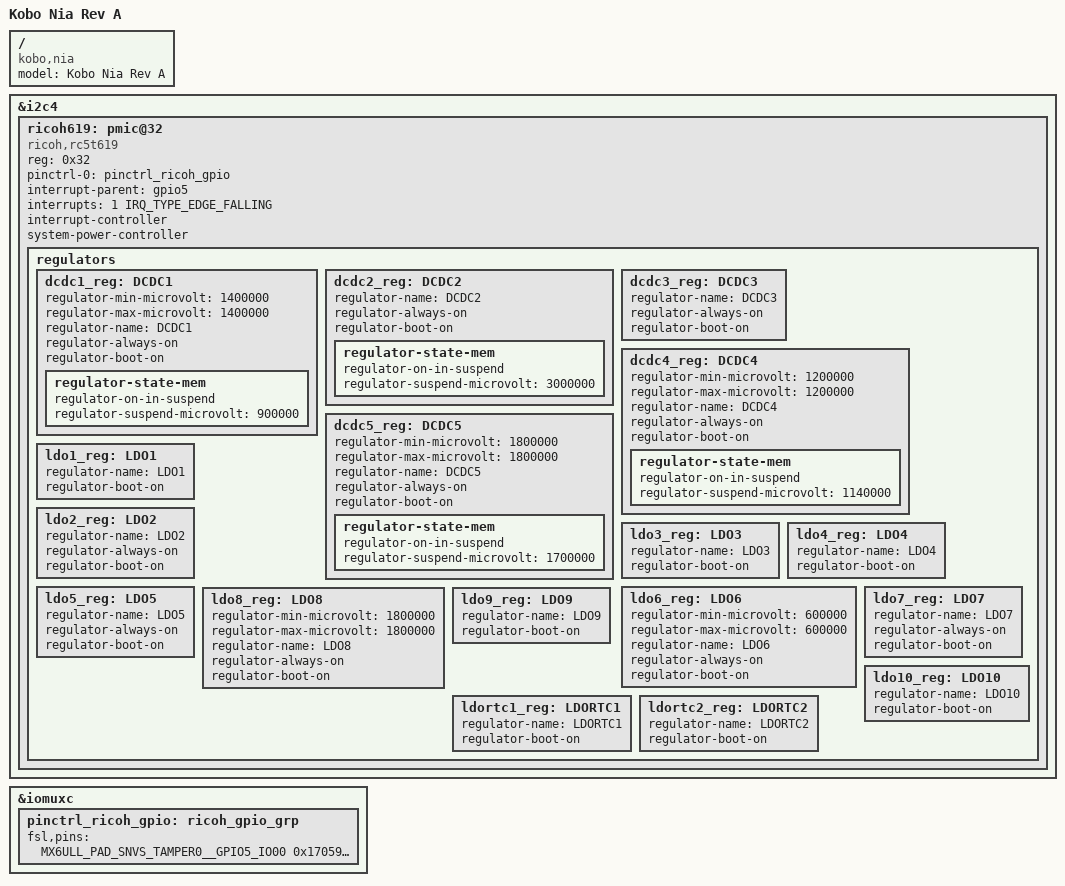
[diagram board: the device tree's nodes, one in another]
/*
 * Copyright (C) 2023 Andreas Kemnade
 *
 * based on works
 * Copyright (C) 2016 Freescale Semiconductor, Inc.
 *
 * This program is free software; you can redistribute it and/or modify
 * it under the terms of the GNU General Public License version 2 as
 * published by the Free Software Foundation.
 */

/dts-v1/;

#include "imx6ull-kobo-nia-common.dtsi"

/ {
	model = "Kobo Nia Rev A";
	compatible = "kobo,nia", "fsl,imx6ull";
};

&i2c4 {
	ricoh619: pmic@32 {
		compatible = "ricoh,rc5t619";
		reg = <0x32>;
		pinctrl-names = "default";
		pinctrl-0 = <&pinctrl_ricoh_gpio>;
		interrupt-parent = <&gpio5>;
		interrupts = <1 IRQ_TYPE_EDGE_FALLING>;
		interrupt-controller;
		#interrupt-cells = <0>;
		system-power-controller;
	
		regulators {
			dcdc1_reg: DCDC1 {
				regulator-min-microvolt = <1400000>;
				regulator-max-microvolt = <1400000>;
				regulator-name = "DCDC1";
				regulator-always-on;
				regulator-boot-on;
				regulator-state-mem {
					regulator-on-in-suspend;
					regulator-suspend-microvolt = <900000>;
				};
			};
			dcdc2_reg: DCDC2 {
				regulator-name = "DCDC2";
				regulator-always-on;
				regulator-boot-on;
				regulator-state-mem {
					regulator-on-in-suspend;
					regulator-suspend-microvolt = <3000000>;
				};
			};
			dcdc3_reg: DCDC3 {
				regulator-name = "DCDC3";
				regulator-always-on;
				regulator-boot-on;
			};
			dcdc4_reg: DCDC4 {
				regulator-min-microvolt = <1200000>;
				regulator-max-microvolt = <1200000>;
				regulator-name = "DCDC4";
				regulator-always-on;
				regulator-boot-on;
				regulator-state-mem {
					regulator-on-in-suspend;
					regulator-suspend-microvolt = <1140000>;
				};
			};
			dcdc5_reg: DCDC5 {
				regulator-min-microvolt = <1800000>;
				regulator-max-microvolt = <1800000>;
				regulator-name = "DCDC5";
				regulator-always-on;
				regulator-boot-on;
				regulator-state-mem {
					regulator-on-in-suspend;
					regulator-suspend-microvolt = <1700000>;
				};
			};
			ldo1_reg: LDO1 {
				regulator-name = "LDO1";
				//regulator-always-on;
				regulator-boot-on;
			};
			ldo2_reg: LDO2 {
				regulator-name = "LDO2";
				regulator-always-on;
				regulator-boot-on;
//				regulator-state-mem {
//					regulator-on-in-suspend;
//					regulator-suspend-microvolt = <3000000>;
//				};
			};
			ldo3_reg: LDO3 {
				regulator-name = "LDO3";
				//regulator-always-on;
				regulator-boot-on;
			};
			ldo4_reg: LDO4 {
				regulator-name = "LDO4";
				//regulator-always-on;
				regulator-boot-on;
			};
			ldo5_reg: LDO5 {
				regulator-name = "LDO5";
				regulator-always-on;
				regulator-boot-on;
			};
			ldo6_reg: LDO6  {
				regulator-min-microvolt = <600000>;
				regulator-max-microvolt = <600000>;
				regulator-name = "LDO6";
				regulator-always-on;
				regulator-boot-on;
			};
			ldo7_reg: LDO7 {
				regulator-name = "LDO7";
				regulator-always-on;
				regulator-boot-on;
			};
			ldo8_reg: LDO8  {
				regulator-min-microvolt = <1800000>;
				regulator-max-microvolt = <1800000>;
				regulator-name = "LDO8";
				regulator-always-on;
				regulator-boot-on;
			};
			ldo9_reg: LDO9 {
				regulator-name = "LDO9";
				//regulator-always-on;
				regulator-boot-on;
			};
			ldo10_reg: LDO10 {
				regulator-name = "LDO10";
				//regulator-always-on;
				regulator-boot-on;
			};
			ldortc1_reg: LDORTC1 {
				regulator-name = "LDORTC1";
				//regulator-always-on;
				regulator-boot-on;
			};
			ldortc2_reg: LDORTC2 {
				regulator-name = "LDORTC2";
				//regulator-always-on;
				regulator-boot-on;
			};
		};
	};
};

&iomuxc {
	pinctrl_ricoh_gpio: ricoh_gpio_grp {
		fsl,pins = <
			MX6ULL_PAD_SNVS_TAMPER0__GPIO5_IO00		0x17059 /* ricoh619 CHG# */
			MX6ULL_PAD_SNVS_TAMPER1__GPIO5_IO01		0x17059 /* ricoh619 irq */
			MX6ULL_PAD_SNVS_TAMPER3__GPIO5_IO03		0x17059 /* ricoh619 bat_low_irq */
		>;
	};

};
